# CC3200 register map
Vendor: Texas Instruments; Series: SimpleLink; File version: 1.0
CPU: CM4 r0p1, little endian, MPU, no FPU, 3 interrupt priority bits
Registers are 32-bit, read-write, reset 0x0 unless marked. A register's access mark holds for its fields unless they carry their own. Offsets are from the block's base; [hi:lo] are bit positions; {n}, {i} and the like mark numbered series; 'fields as' and 'values as' point back to an identical list.

## MCSPI — SSPI
Base 0x44020000
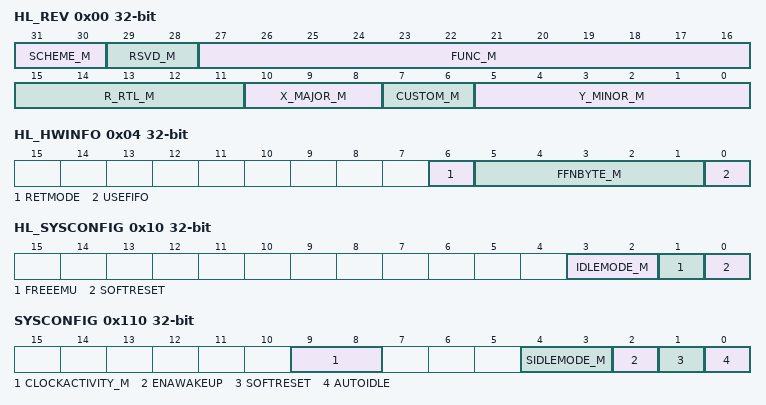
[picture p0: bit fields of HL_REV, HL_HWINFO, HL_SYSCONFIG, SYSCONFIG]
0x00 HL_REV — MCSPI_HL_REV
  [31:30] SCHEME_M — MCSPI_HL_REV
  [29:28] RSVD_M — MCSPI_HL_REV
  [27:16] FUNC_M — MCSPI_HL_REV
  [15:11] R_RTL_M — MCSPI_HL_REV
  [10:8] X_MAJOR_M — MCSPI_HL_REV
  [7:6] CUSTOM_M — MCSPI_HL_REV
  [5:0] Y_MINOR_M — MCSPI_HL_REV
0x04 HL_HWINFO — MCSPI_HL_HWINFO
  [6] RETMODE — MCSPI_HL_HWINFO
  [5:1] FFNBYTE_M — MCSPI_HL_HWINFO
  [0] USEFIFO — MCSPI_HL_HWINFO
0x10 HL_SYSCONFIG — MCSPI_HL_SYSCONFIG
  [3:2] IDLEMODE_M — MCSPI_HL_SYSCONFIG
  [1] FREEEMU — MCSPI_HL_SYSCONFIG
  [0] SOFTRESET — MCSPI_HL_SYSCONFIG
0x100 REVISION — MCSPI_REVISION
  [7:0] REV_M
0x110 SYSCONFIG — MCSPI_SYSCONFIG
  [9:8] CLOCKACTIVITY_M — MCSPI_SYSCONFIG
  [4:3] SIDLEMODE_M — MCSPI_SYSCONFIG
  [2] ENAWAKEUP — MCSPI_SYSCONFIG
  [1] SOFTRESET — MCSPI_SYSCONFIG
  [0] AUTOIDLE — MCSPI_SYSCONFIG
0x114 SYSSTATUS — MCSPI_SYSSTATUS
  [0] RESETDONE
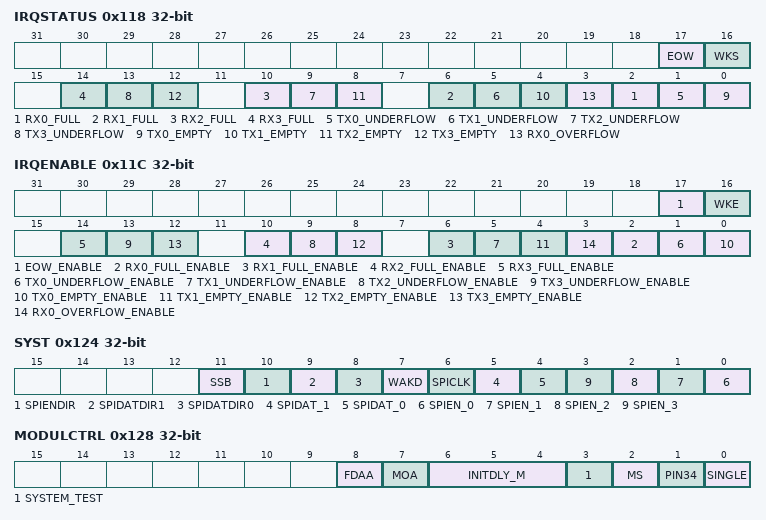
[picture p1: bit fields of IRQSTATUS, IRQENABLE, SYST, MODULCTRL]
0x118 IRQSTATUS — MCSPI_IRQSTATUS
  [17] EOW — MCSPI_IRQSTATUS
  [16] WKS — MCSPI_IRQSTATUS
  [4n+2] RX{n}_FULL (n=0..3) — MCSPI_IRQSTATUS
  [4n+1] TX{n}_UNDERFLOW (n=0..3) — MCSPI_IRQSTATUS
  [4n] TX{n}_EMPTY (n=0..3) — MCSPI_IRQSTATUS
  [3] RX0_OVERFLOW — MCSPI_IRQSTATUS
0x11C IRQENABLE — MCSPI_IRQENABLE
  [17] EOW_ENABLE — MCSPI_IRQENABLE
  [16] WKE — MCSPI_IRQENABLE
  [4n+2] RX{n}_FULL_ENABLE (n=0..3) — MCSPI_IRQENABLE
  [4n+1] TX{n}_UNDERFLOW_ENABLE (n=0..3) — MCSPI_IRQENABLE
  [4n] TX{n}_EMPTY_ENABLE (n=0..3) — MCSPI_IRQENABLE
  [3] RX0_OVERFLOW_ENABLE — MCSPI_IRQENABLE
0x120 WAKEUPENABLE — MCSPI_WAKEUPENABLE
  [0] WKEN
0x124 SYST — MCSPI_SYST
  [11] SSB — MCSPI_SYST
  [10] SPIENDIR — MCSPI_SYST
  [9] SPIDATDIR1 — MCSPI_SYST
  [8] SPIDATDIR0 — MCSPI_SYST
  [7] WAKD — MCSPI_SYST
  [6] SPICLK — MCSPI_SYST
  [5] SPIDAT_1 — MCSPI_SYST
  [4] SPIDAT_0 — MCSPI_SYST
  [n] SPIEN_{n} (n=0..3) — MCSPI_SYST
0x128 MODULCTRL — MCSPI_MODULCTRL
  [8] FDAA — MCSPI_MODULCTRL
  [7] MOA — MCSPI_MODULCTRL
  [6:4] INITDLY_M — MCSPI_MODULCTRL
  [3] SYSTEM_TEST — MCSPI_MODULCTRL
  [2] MS — MCSPI_MODULCTRL
  [1] PIN34 — MCSPI_MODULCTRL
  [0] SINGLE — MCSPI_MODULCTRL
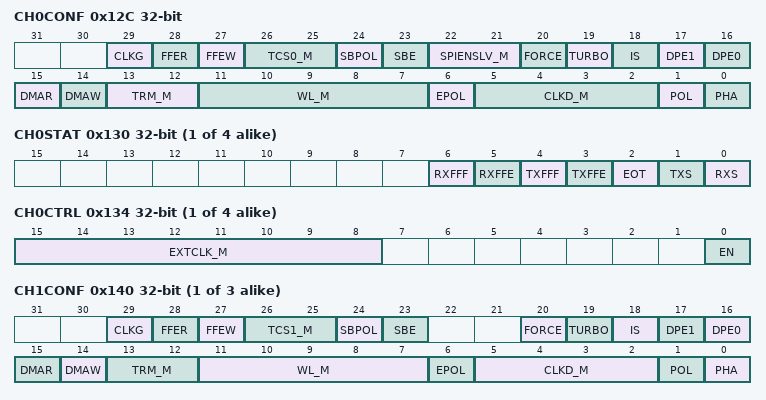
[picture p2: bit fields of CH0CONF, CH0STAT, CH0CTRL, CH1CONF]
0x12C CH0CONF — MCSPI_CH0CONF
  [29] CLKG — MCSPI_CH0CONF
  [28] FFER — MCSPI_CH0CONF
  [27] FFEW — MCSPI_CH0CONF
  [26:25] TCS0_M — MCSPI_CH0CONF
  [24] SBPOL — MCSPI_CH0CONF
  [23] SBE — MCSPI_CH0CONF
  [22:21] SPIENSLV_M — MCSPI_CH0CONF
  [20] FORCE — MCSPI_CH0CONF
  [19] TURBO — MCSPI_CH0CONF
  [18] IS — MCSPI_CH0CONF
  [17] DPE1 — MCSPI_CH0CONF
  [16] DPE0 — MCSPI_CH0CONF
  [15] DMAR — MCSPI_CH0CONF
  [14] DMAW — MCSPI_CH0CONF
  [13:12] TRM_M — MCSPI_CH0CONF
  [11:7] WL_M — MCSPI_CH0CONF
  [6] EPOL — MCSPI_CH0CONF
  [5:2] CLKD_M — MCSPI_CH0CONF
  [1] POL — MCSPI_CH0CONF
  [0] PHA — MCSPI_CH0CONF
{0x130+0x14*i} CH{i}STAT (i=0..3) — MCSPI_CH{i}STAT
  [6] RXFFF — MCSPI_CH{i}STAT
  [5] RXFFE — MCSPI_CH{i}STAT
  [4] TXFFF — MCSPI_CH{i}STAT
  [3] TXFFE — MCSPI_CH{i}STAT
  [2] EOT — MCSPI_CH{i}STAT
  [1] TXS — MCSPI_CH{i}STAT
  [0] RXS — MCSPI_CH{i}STAT
{0x134+0x14*i} CH{i}CTRL (i=0..3) — MCSPI_CH{i}CTRL
  [15:8] EXTCLK_M — MCSPI_CH{i}CTRL
  [0] EN — MCSPI_CH{i}CTRL
{0x138+0x14*i} TX{i} (i=0..3) — MCSPI_TX{i}
  [31:0] TDATA_M
{0x13C+0x14*i} RX{i} (i=0..3) — MCSPI_RX{i}
  [31:0] RDATA_M
{0x12C+0x14*i} CH{i}CONF (i=1..3) — MCSPI_CH{i}CONF
  [29] CLKG — MCSPI_CH{i}CONF
  [28] FFER — MCSPI_CH{i}CONF
  [27] FFEW — MCSPI_CH{i}CONF
  [26:25] TCS{i}_M — MCSPI_CH{i}CONF
  [24] SBPOL — MCSPI_CH{i}CONF
  [23] SBE — MCSPI_CH{i}CONF
  [20] FORCE — MCSPI_CH{i}CONF
  [19] TURBO — MCSPI_CH{i}CONF
  [18] IS — MCSPI_CH{i}CONF
  [17] DPE1 — MCSPI_CH{i}CONF
  [16] DPE0 — MCSPI_CH{i}CONF
  [15] DMAR — MCSPI_CH{i}CONF
  [14] DMAW — MCSPI_CH{i}CONF
  [13:12] TRM_M — MCSPI_CH{i}CONF
  [11:7] WL_M — MCSPI_CH{i}CONF
  [6] EPOL — MCSPI_CH{i}CONF
  [5:2] CLKD_M — MCSPI_CH{i}CONF
  [1] POL — MCSPI_CH{i}CONF
  [0] PHA — MCSPI_CH{i}CONF
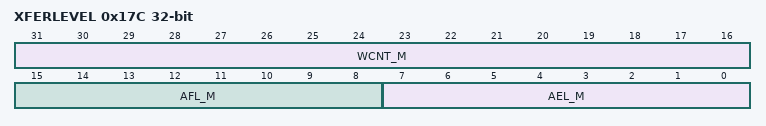
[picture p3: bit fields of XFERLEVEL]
0x17C XFERLEVEL — MCSPI_XFERLEVEL
  [31:16] WCNT_M — MCSPI_XFERLEVEL
  [15:8] AFL_M — MCSPI_XFERLEVEL
  [7:0] AEL_M — MCSPI_XFERLEVEL
0x180 DAFTX — MCSPI_DAFTX
  [31:0] DAFTDATA_M
0x1A0 DAFRX — MCSPI_DAFRX
  [31:0] DAFRDATA_M

## MCSPI — GSPI
Base 0x44021000
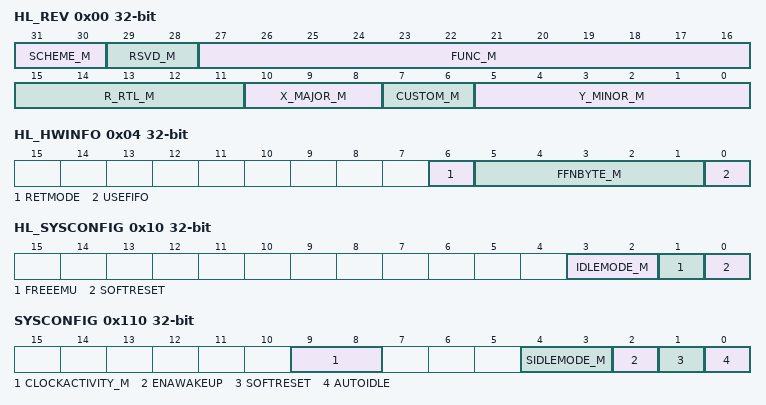
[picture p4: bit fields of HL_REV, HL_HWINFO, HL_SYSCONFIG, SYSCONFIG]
0x00 HL_REV — MCSPI_HL_REV
  fields as HL_REV
0x04 HL_HWINFO — MCSPI_HL_HWINFO
  fields as HL_HWINFO
0x10 HL_SYSCONFIG — MCSPI_HL_SYSCONFIG
  fields as HL_SYSCONFIG
0x100 REVISION — MCSPI_REVISION
  [7:0] REV_M
0x110 SYSCONFIG — MCSPI_SYSCONFIG
  fields as SYSCONFIG
0x114 SYSSTATUS — MCSPI_SYSSTATUS
  [0] RESETDONE
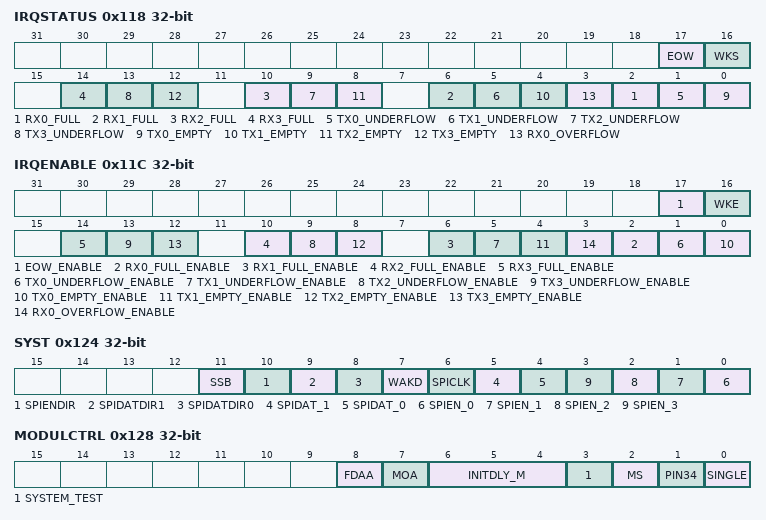
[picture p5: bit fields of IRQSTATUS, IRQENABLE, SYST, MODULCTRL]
0x118 IRQSTATUS — MCSPI_IRQSTATUS
  fields as IRQSTATUS
0x11C IRQENABLE — MCSPI_IRQENABLE
  fields as IRQENABLE
0x120 WAKEUPENABLE — MCSPI_WAKEUPENABLE
  [0] WKEN
0x124 SYST — MCSPI_SYST
  fields as SYST
0x128 MODULCTRL — MCSPI_MODULCTRL
  fields as MODULCTRL
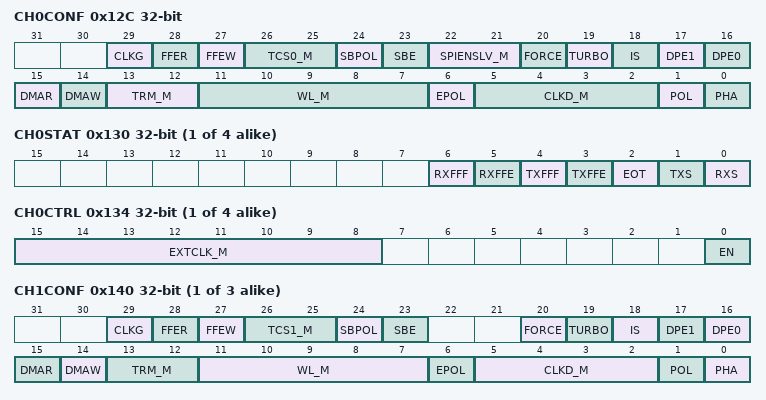
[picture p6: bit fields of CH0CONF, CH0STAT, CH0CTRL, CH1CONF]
0x12C CH0CONF — MCSPI_CH0CONF
  fields as CH0CONF
{0x130+0x14*i} CH{i}STAT (i=0..3) — MCSPI_CH{i}STAT
  fields as CH0STAT
{0x134+0x14*i} CH{i}CTRL (i=0..3) — MCSPI_CH{i}CTRL
  [15:8] EXTCLK_M — MCSPI_CH{i}CTRL
  [0] EN — MCSPI_CH{i}CTRL
{0x138+0x14*i} TX{i} (i=0..3) — MCSPI_TX{i}
  [31:0] TDATA_M
{0x13C+0x14*i} RX{i} (i=0..3) — MCSPI_RX{i}
  [31:0] RDATA_M
{0x12C+0x14*i} CH{i}CONF (i=1..3) — MCSPI_CH{i}CONF
  fields as CH1CONF
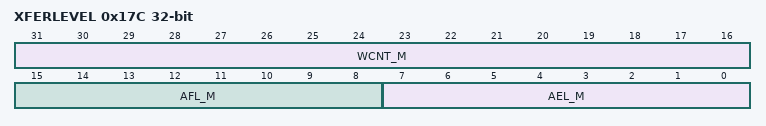
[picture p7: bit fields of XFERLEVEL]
0x17C XFERLEVEL — MCSPI_XFERLEVEL
  fields as XFERLEVEL
0x180 DAFTX — MCSPI_DAFTX
  [31:0] DAFTDATA_M
0x1A0 DAFRX — MCSPI_DAFRX
  [31:0] DAFRDATA_M

## MCSPI — LSPI
Base 0x44022000
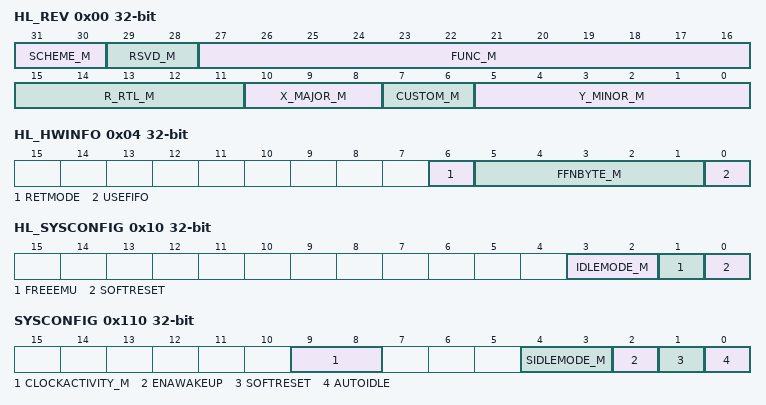
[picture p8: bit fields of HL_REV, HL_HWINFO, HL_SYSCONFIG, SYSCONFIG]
0x00 HL_REV — MCSPI_HL_REV
  fields as HL_REV
0x04 HL_HWINFO — MCSPI_HL_HWINFO
  fields as HL_HWINFO
0x10 HL_SYSCONFIG — MCSPI_HL_SYSCONFIG
  fields as HL_SYSCONFIG
0x100 REVISION — MCSPI_REVISION
  [7:0] REV_M
0x110 SYSCONFIG — MCSPI_SYSCONFIG
  fields as SYSCONFIG
0x114 SYSSTATUS — MCSPI_SYSSTATUS
  [0] RESETDONE
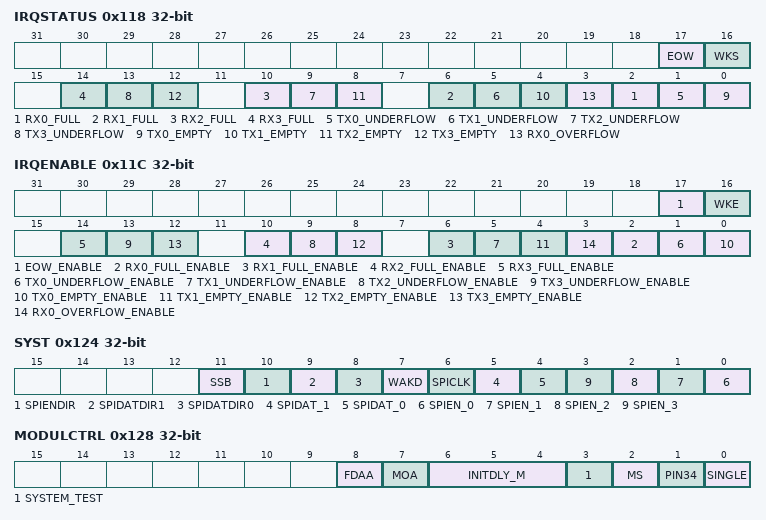
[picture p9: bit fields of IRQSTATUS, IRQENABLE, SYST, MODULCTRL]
0x118 IRQSTATUS — MCSPI_IRQSTATUS
  fields as IRQSTATUS
0x11C IRQENABLE — MCSPI_IRQENABLE
  fields as IRQENABLE
0x120 WAKEUPENABLE — MCSPI_WAKEUPENABLE
  [0] WKEN
0x124 SYST — MCSPI_SYST
  fields as SYST
0x128 MODULCTRL — MCSPI_MODULCTRL
  fields as MODULCTRL
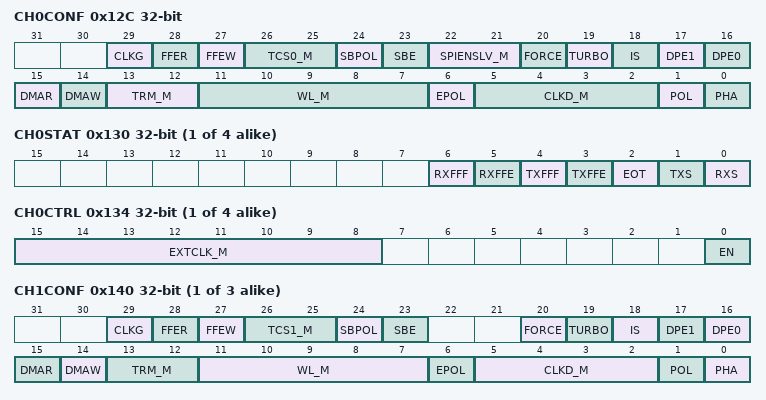
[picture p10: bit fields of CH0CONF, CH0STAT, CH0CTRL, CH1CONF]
0x12C CH0CONF — MCSPI_CH0CONF
  fields as CH0CONF
{0x130+0x14*i} CH{i}STAT (i=0..3) — MCSPI_CH{i}STAT
  fields as CH0STAT
{0x134+0x14*i} CH{i}CTRL (i=0..3) — MCSPI_CH{i}CTRL
  [15:8] EXTCLK_M — MCSPI_CH{i}CTRL
  [0] EN — MCSPI_CH{i}CTRL
{0x138+0x14*i} TX{i} (i=0..3) — MCSPI_TX{i}
  [31:0] TDATA_M
{0x13C+0x14*i} RX{i} (i=0..3) — MCSPI_RX{i}
  [31:0] RDATA_M
{0x12C+0x14*i} CH{i}CONF (i=1..3) — MCSPI_CH{i}CONF
  fields as CH1CONF
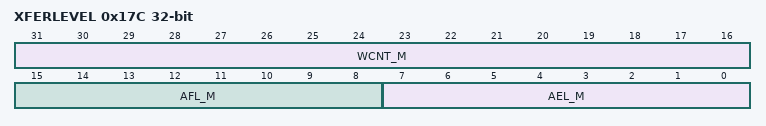
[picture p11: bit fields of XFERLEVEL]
0x17C XFERLEVEL — MCSPI_XFERLEVEL
  fields as XFERLEVEL
0x180 DAFTX — MCSPI_DAFTX
  [31:0] DAFTDATA_M
0x1A0 DAFRX — MCSPI_DAFRX
  [31:0] DAFRDATA_M
